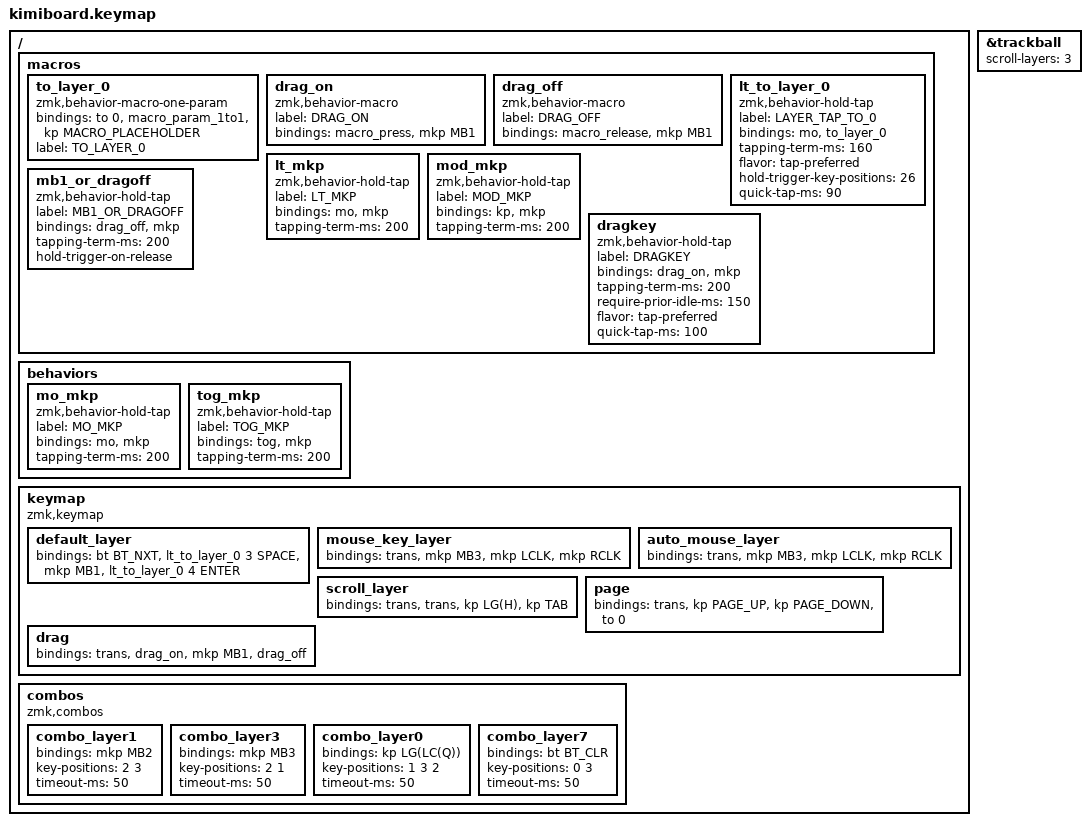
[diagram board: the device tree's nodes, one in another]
#include <dt-bindings/zmk/mouse.h>
#include <behaviors/rgbled_widget.dtsi>
#include <behaviors.dtsi>
#include <dt-bindings/zmk/bt.h>
#include <dt-bindings/zmk/keys.h>
#include <dt-bindings/zmk/pointing.h>

&trackball { scroll-layers = <3>; };

/ {
    macros {
        to_layer_0: to_layer_0 {
            compatible = "zmk,behavior-macro-one-param";
            #binding-cells = <1>;
            bindings = <&to 0 &macro_param_1to1 &kp MACRO_PLACEHOLDER>;
            label = "TO_LAYER_0";
        };

        /* Keep MB1 pressed */

        drag_on: drag_on {
            compatible = "zmk,behavior-macro";
            label = "DRAG_ON";
            #binding-cells = <0>;
            bindings = <&macro_press>, <&mkp MB1>;
        };

        /* Release MB1 */

        drag_off: drag_off {
            compatible = "zmk,behavior-macro";
            label = "DRAG_OFF";
            #binding-cells = <0>;
            bindings = <&macro_release>, <&mkp MB1>;
        };

        lt_to_layer_0: lt_to_layer_0 {
            compatible = "zmk,behavior-hold-tap";
            label = "LAYER_TAP_TO_0";
            bindings = <&mo>, <&to_layer_0>;

            #binding-cells = <2>;
            tapping-term-ms = <160>;
            flavor = "tap-preferred";
            hold-trigger-key-positions = <26>;
            quick-tap-ms = <90>;
        };

        lt_mkp: lt_mkp {
            compatible = "zmk,behavior-hold-tap";
            label = "LT_MKP";
            bindings = <&mo>, <&mkp>;

            #binding-cells = <2>;
            tapping-term-ms = <200>;
        };

        mod_mkp: mod_mkp {
            compatible = "zmk,behavior-hold-tap";
            label = "MOD_MKP";
            bindings = <&kp>, <&mkp>;

            #binding-cells = <2>;
            tapping-term-ms = <200>;
        };

        /* Tap: normal MB1 click / Hold: drag off (release MB1) */

        mb1_or_dragoff: mb1_or_dragoff {
            compatible = "zmk,behavior-hold-tap";
            label = "MB1_OR_DRAGOFF";
            bindings = <&drag_off>, <&mkp>;

            #binding-cells = <2>;
            tapping-term-ms = <200>;
            hold-trigger-on-release;
        };

        dragkey: dragkey {
            compatible = "zmk,behavior-hold-tap";
            label = "DRAGKEY";
            bindings = <&drag_on>, <&mkp>;

            #binding-cells = <2>;
            tapping-term-ms = <200>;
            require-prior-idle-ms = <150>;
            flavor = "tap-preferred";
            quick-tap-ms = <100>;
        };
    };

    behaviors {
        mo_mkp: mo_mkp {
            compatible = "zmk,behavior-hold-tap";
            label = "MO_MKP";
            bindings = <&mo>, <&mkp>;

            #binding-cells = <2>;
            tapping-term-ms = <200>;
        };

        tog_mkp: tog_mkp {
            compatible = "zmk,behavior-hold-tap";
            label = "TOG_MKP";
            bindings = <&tog>, <&mkp>;

            #binding-cells = <2>;
            tapping-term-ms = <200>;
        };
    };

    keymap {
        compatible = "zmk,keymap";

        default_layer {
            bindings = <
&bt BT_NXT  &lt_to_layer_0 3 SPACE  &mkp MB1  &lt_to_layer_0 4 ENTER
            >;
        };

        mouse_key_layer {
            bindings = <
&trans  &mkp MB3  &mkp LCLK  &mkp RCLK
            >;
        };

        auto_mouse_layer {
            bindings = <
&trans  &mkp MB3  &mkp LCLK  &mkp RCLK
            >;
        };

        scroll_layer {
            bindings = <
&trans  &trans  &kp LG(H)  &kp TAB
            >;
        };

        page {
            bindings = <
&trans  &kp PAGE_UP  &kp PAGE_DOWN  &to 0
            >;
        };

        drag {
            bindings = <
&trans  &drag_on  &mkp MB1  &drag_off
            >;
        };
    };

    combos {
        compatible = "zmk,combos";

        combo_layer1 {
            bindings = <&mkp MB2>;
            key-positions = <2 3>;
            timeout-ms = <50>;
        };

        combo_layer3 {
            bindings = <&mkp MB3>;
            key-positions = <2 1>;
            timeout-ms = <50>;
        };

        combo_layer0 {
            bindings = <&kp LG(LC(Q))>;
            key-positions = <1 3 2>;
            timeout-ms = <50>;
        };

        combo_layer7 {
            bindings = <&bt BT_CLR>;
            key-positions = <0 3>;
            timeout-ms = <50>;
        };
    };
};
